# 3066H register map
File version: 1.0
Registers are 32-bit, access per field, reset 0x0 unless marked. A register's access mark holds for its fields unless they carry their own. Offsets are from the block's base; [hi:lo] are bit positions; {n}, {i} and the like mark numbered series.

## MCAN0 — MCAN0 peripheral interface
Base 0x14680000
Same registers: MCAN1 0x14684000, MCAN2 0x14688000
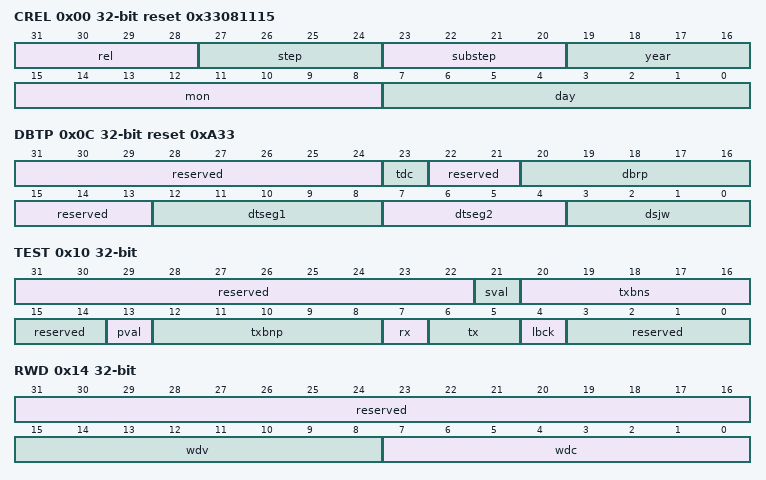
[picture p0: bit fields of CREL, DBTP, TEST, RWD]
0x00 CREL ro reset 0x33081115 — CREL为Core发布寄存器。
  [31:28] rel — 版本信息。
  [27:24] step — 版本信息。
  [23:20] substep — 版本信息。
  [19:16] year — 版本信息。
  [15:8] mon — 版本信息。
  [7:0] day — 版本信息。
0x04 ENDN ro reset 0x87654321 — ENDN为MCAN字节序寄存器。
  [31:0] etv — 字节序测试值。测试值为0x87654321。
0x0C DBTP reset 0xA33 — DBTP为MCAN数据位时间和预分频寄存器。 当MCAN通信时钟为8MHz时，复位值0x00000A33会将MCAN数据阶段（Data phase）的比特率配置为500kbit/s。通过DBTP配置的CAN FD数据阶段（Data phase）比特率不能小于通过NBTP配置的仲裁阶段（Arbitration phase）比特率。
  [31:24] reserved ro — 保留。
  [23] tdc rw — 发送延迟补偿。 0：禁止发送延迟补偿； 1：使能发送延迟补偿。
  [22:21] reserved ro — 保留。
  [20:16] dbrp rw — 数据比特率预分频。生成位时间片的MCAN通信时钟预分频值，位时间为该时间片的倍数。预分频有效值为0到31，当TDC=1时，范围被限制在0到1，硬件实际使用值为编程值加1。
  [15:13] reserved ro — 保留。
  [12:8] dtseg1 rw — 采样点之前的数据时间。有效值为0到31，硬件实际使用值为编程值加1。
  [7:4] dtseg2 rw — 采样点之后的数据时间。有效值为1到15，硬件实际使用值为编程值加1。
  [3:0] dsjw rw — 数据（重新）同步跳转宽度。有效值为0到15，硬件实际使用值为编程值加1。
0x10 TEST — TEST为MCAN测试寄存器。 bit[7]的复位值由CAN_RX引脚的实际电平决定。仅当CCCR[test]位被置1后，才能对该测试寄存器进行写访问。当CCCR[test]位被清零时，所有测试寄存器功能都会设为其复位值。回环模式和软件控制MCAN_TX引脚属于硬件测试模式。TX配置为非0b00时可能会干扰CAN总线上的消息传输。
  [31:22] reserved ro — 保留。
  [21] sval rw — TNBNS是否有效。 0：TXBNS的值无效； 1：TXBNS的值有效。
  [20:16] txbns rw — 已开始发送的缓冲区编号。 最后开始发送的发送缓冲区编号。 当SVAL位被置1时有效，有效范围为0~31。
  [15:14] reserved ro — 保留。
  [13] pval ro — TXNBP是否有效。 0：TXBNP的值无效； 1：TXBNP的值有效。
  [12:8] txbnp ro — 已准备好发送的缓冲区编号。 准备好发送的发送缓冲区编号。 当PVAL位被置1时有效，有效范围为0~31。
  [7] rx ro — 接收管脚。 监测到的CAN_RX管脚的实际值。 0：CAN总线为显性（CAN_RX=0）； 1：CAN总线为隐性（CAN_RX=1）。
  [6:5] tx rw — 发送引脚控制。 00：复位值，MCAN_TX引脚由CAN内核控制，在CAN位时间结束时更新； 01：可以在MCAN_TX引脚监测采样点； 10：MCAN_TX引脚输出显性电平（0）； 11：MCAN_TX引脚输出隐性电平（1）。
  [4] lbck rw — 环回模式。 0：复位值，禁止环回模式； 1：使能环回模式（详见26.3.2.10 外部环回模式和26.3.2.11 内部环回模式章节）。
  [3:0] reserved ro — 保留。
0x14 RWD — RWD为MCAN RAM看门狗寄存器。RAM看门狗会监视消息RAM的READY信号输出。对消息RAM进行访问时，会启动消息RAM看门狗计数器，该计数器的起始值由RWD[wdc]位进行配置。当消息RAM通过激活其READY信号输出，指示访问成功完成时，该计数器会重新载入RWD[wdc]的值。如果计数器递减为0之前消息RAM没有响应，计数器将停止计数，并将中断标志IR[wdi]位置1。RAM看门狗计数器由MCAN控制逻辑时钟计数。
  [31:16] reserved ro — 保留。
  [15:8] wdv ro — 看门狗计数值。 消息RAM看门狗计数器的实际值。
  [7:0] wdc rw — 看门狗配置。 消息RAM看门狗计数器的起始值。 如果使用初始值0x00，则计数器被禁止。
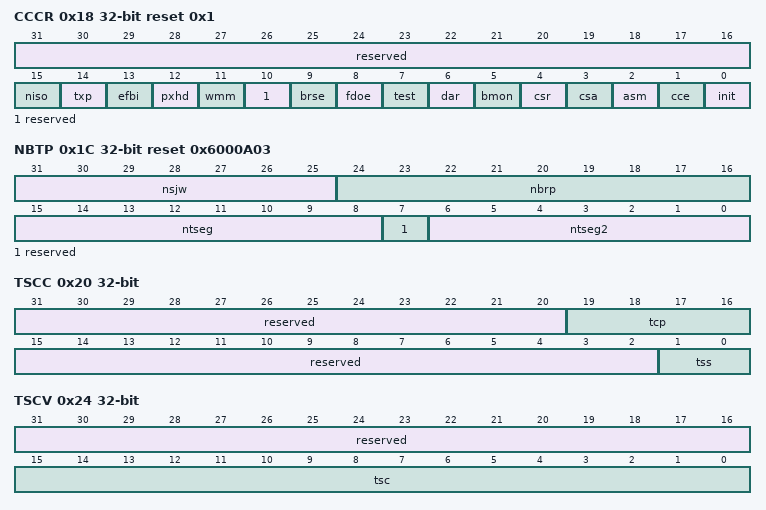
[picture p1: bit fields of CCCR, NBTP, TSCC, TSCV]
0x18 CCCR reset 0x1 — CCCR为MCAN CC控制寄存器。
  [31:16] reserved ro — 保留。
  [15] niso rw — 非ISO模式选择。 0：使用ISO 11898-1:2015规定的CAN FD帧格式； 1：使用Bosch CAN FD规范V1.0规定的CAN FD帧格式。
  [14] txp rw — 传输暂停。 若该位被置为1，则MCAN在成功传输完一帧数据后会暂停两个位时间，再进行下一帧数据的传输。 0：禁止传输暂停； 1：使能传输暂停。
  [13] efbi rw — 总线同步期间的边沿滤波。 0：禁止边沿滤波； 1：需要两个连续的显性tq才能检测硬同步边沿。
  [12] pxhd rw — 协议异常处理禁止。 0：使能协议异常处理； 1：禁止协议异常处理。 注意：当协议异常处理被禁止时，MCAN将在检测到协议异常条件时传输错误帧。
  [11] wmm rw — 宽消息标记。 当使用16位宽消息标记（WMM=1）时，发送事件FIFO中的16位内部时间戳是无效的。 0：使用8位消息标记； 1：使用16位消息标记，替换发送事件FIFO中的16位时间戳。
  [10] reserved ro — 保留。
  [9] brse rw — 比特率切换。 0：禁止发送时进行比特率切换； 1：使能发送时进行比特率切换。 注意：当CAN-FD模式无效（FDOE=0）时，BRSE的设置不起作用。
  [8] fdoe rw — FD模式使能。 0：禁止FD模式； 1：使能FD模式。
  [7] test rw — 测试模式使能。 0：正常模式，测试寄存器TEST保持复位值； 1：测试模式，使能写访问测试寄存器TEST。
  [6] dar rw — 禁止自动重发。 0：使能允许自动重发未成功发送的消息； 1：禁止自动重发。
  [5] bmon rw — 总线静默模式。 仅当CCE和INIT位均置1时，主机才能将MON位置1。此位可随时通过主机复位。 0：禁止总线静默模式； 1：使能总线静默模式。
  [4] csr rw — 时钟停止请求。 当已请求时钟停止时，在所有挂起的传输请求均已完成且CAN总线达到空闲状态之后，INIT位和CSA位将会依次被置1。 0：未请求时钟停止； 1：已请求时钟停止。
  [3] csa ro — 时钟停止确认。 0：未确认时钟停止请求； 1：已确认时钟停止请求，可以通过停止控制逻辑时钟和通信时钟将MCAN设为掉电状态。
  [2] asm rw — 受限操作模式。 仅当CCE和INIT均置1时，主机才能将ASM位置1。此位可随时通过主机复位。 有关受限工作模式的说明，请参阅受限工作模式章节。 0：正常模式； 1：受限工作模式。
  [1] cce rw — 配置更改使能。 0：CPU对受保护的配置寄存器无写访问权限； 1：CPU对受保护的配置寄存器有写访问权限（当INIT=1时）。
  [0] init rw — 初始化。 0：正常工作； 1：启动初始化； 注意：由于两个时钟域之间存在同步机制，INIT的值在写入后可能会有一定延迟才能被正确读取。因此，在重新设定INIT值之前，请确认之前的设定值确实已被写入。
0x1C NBTP reset 0x6000A03 — NBTP为MCAN标称位时间和预分频寄存器。仅当CCCR[cce]和CCCR[init]位均被置1时，才能对该寄存器进行写访问。CAN标称位时间的可编程范围为4到385个时间片（Time quanta，tq）。CAN时间片的可编程范围为1到512个MCAN通信时钟周期（Minimum time quantum， mtq）。 tq = (NBRP + 1)mtq。NTSEG1为Prop_Seg与Phase_Seg1之和。NTSEG2为Phase_Seg2。因此，位时间的长度为（编程值）[NTSEG1 + NTSEG2 + 3] tq 或（功能值）[Sync_Seg + Prop_Seg + Phase_Seg1 + Phase_Seg2] tq。信息处理时间（IPT）为零，这意味着下一位数据在采样点之后的第一个时钟边沿可用。 当MCAN时钟为8MHz时，复位值0x06000A03会将MCAN的比特率配置为500kbit/s。
  [31:25] nsjw rw — 标称（重）同步跳转宽度。 有效值为0到127，硬件实际使用值为编程值加1。
  [24:16] nbrp rw — 标称比特率预分频。 生成位时间片的MCAN通信时钟预分频值，位时间为该时间片的倍数。预分频有效值为0到511，硬件实际使用值为编程值加1。
  [15:8] ntseg rw — 采样点之前的标称时间段。 有效值为1到255，硬件实际使用值为编程值加1。
  [7] reserved ro — 保留。
  [6:0] ntseg2 rw — 采样点之后的标称时间段。 有效值为1到127，硬件实际使用值为编程值加1。
0x20 TSCC — TSCC为MCAN时间戳计数器配置寄存器。该寄存器用于配置内部16位时间戳计数器。内部时间戳处理的介绍请参见26.3.3 时间戳生成章节。
  [31:20] reserved ro — 保留。
  [19:16] tcp rw — 时间戳计数器预分频。 将时间戳和超时计数器时间单位配置为CAN位时间的1~16倍。 有效设定值为0~15，硬件实际使用值为编程值加1。
  [15:2] reserved ro — 保留。
  [1:0] tss rw — 时间戳选择。 00：时间戳计数器的值一直为0x0000； 01：时间戳计数器的值根据TCP递增； 10：禁止配置； 11：时间戳计数器的值一直为0x0000（等同于配置值“00”）。
0x24 TSCV access not given — TSCV为MCAN时间戳计数器值寄存器。
  [31:16] reserved ro — 保留。
  [15:0] tsc — 时间戳计数器。 在接收到或发送SOF（Start Of Frame）时捕获的内部时间戳计数器值。 当TSCC[tss]=0b01时，时间戳计数器以CAN位时间的1~16倍进行递增，具体倍数由TSCC[tcp]的设定值决定。计数回卷时，中断标志IR[tsw]会被置1。写操作会将计数器清零。 注意： “回卷”是指时间戳计数器的值从非零变为零，并不是由于TSCV的写操作引起的清零。字节访问时，对该寄存器的任何一个字节进行写操作都会导致时间戳寄存器被清零。
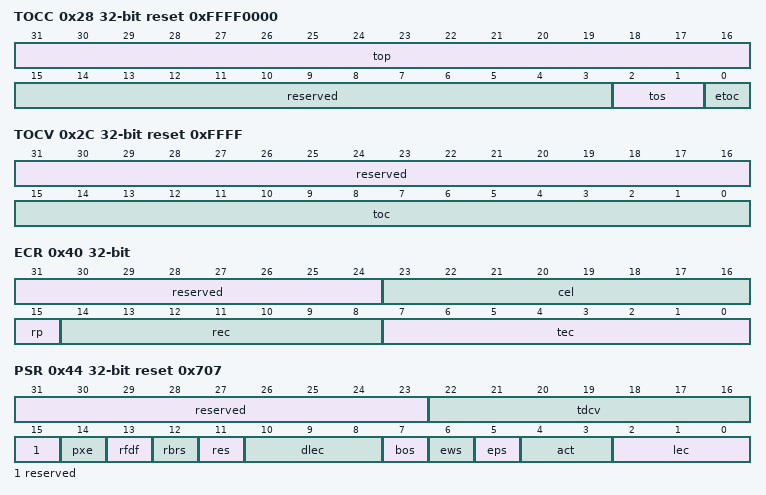
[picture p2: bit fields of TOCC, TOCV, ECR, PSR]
0x28 TOCC reset 0xFFFF0000 — TOCC为MCAN超时计数器配置寄存器。超时计数器的介绍请参见26.3.4 超时计数器章节。
  [31:16] top rw — 超时周期。 超时计数器（递减计数器）的起始值，配置超时周期。
  [15:3] reserved ro — 保留。
  [2:1] tos rw — 超时选择。 在连续模式下操作时，对TOCV进行写访问会将计数器预设为TOCC[top]配置的值，并继续向下递减。当超时计数器由其中一个FIFO控制时，空FIFO会将计数器预设为TOCC[top]配置的值。当第一个FIFO元素被存储后，计数器开始递减计数。 00：连续模式； 01：由发送事件FIFO控制超时； 10：由接收FIFO0控制超时； 11：由接收FIFO1控制超时。
  [0] etoc rw — 超时计数器使能。 0：禁止超时计数器； 1：使能超时计数器。
0x2C TOCV access not given reset 0xFFFF — TOCV为MCAN超时计数器值寄存器。
  [31:16] reserved ro — 保留。
  [15:0] toc — 超时计数器。 超时计数器以CAN位时间的1~16倍进行递减，具体倍数由TSCC[tcp]的设定值决定。 当计数器递减到零时，中断标志位IR[too]会被置1，计数器停止计数。可以通过TOCC[tos]来设置启动和复位（或重启）条件。 注意：字节访问时，当TOCC[tos]=0b00时，对该寄存器的任何一个字节进行写操作都会将超时计数器预设为TOCC[top]配置的值。
0x40 ECR ro — ECR为MCAN错误计数器寄存器。
  [31:24] reserved — 保留。
  [23:16] cel — CAN错误记录。 当CAN协议错误导致发送错误计数器TEC或接收错误计数器REC递增时，该错误记录计数器CEL都会递增。计数器值达到0xFF时，会停止计数。只有RP位置位但REC没有变化时，CEL不会递增。CEL在REC和TEC增加后递增。 对CEL进行读访问会复位计数器。计数器值达到0xFF时，停止计数，TEC或REC下一次增加时中断标志IR[elo]置位。 注意：字节访问时，读取寄存器的字节2会将CEL清零，读取字节3、1或0没有影响。如果CCCR[asm]被置为1，则检测到CAN协议错误时，CAN协议控制器不会使TEC和REC递增，但CEL仍会递增。
  [15] rp — 接收错误被动。 0：接收错误计数器低于错误被动级别128； 1：接收错误计数器已达到错误被动级别128。
  [14:8] rec — 接收错误计数器。 接收错误计数器的实际状态，计数值范围为0x00~0x7F。
  [7:0] tec — 发送错误计数器。 发送错误计数器的实际状态，计数值范围为0x00~0xFF。
0x44 PSR ro reset 0x707 — PSR为MCAN协议状态寄存器。
  [31:23] reserved — 保留。
  [22:16] tdcv — 发送延迟补偿值。 实际的发送延迟补偿值，有效值为0~127个mtq。 第二采样点（Secondary Sample Point， SSP）的位置，由CAN_TX引脚到CAN_RX引脚之间测得的迟延值与TDCR[tdco]之和决定。在数据阶段（Data phase），SSP位置是发送位的起始点与第二采样点间的mtq数。
  [15] reserved — 保留。
  [14] pxe — 协议异常事件。 0：自上次读访问后未发生协议异常事件； 1：已发生协议异常事件； 访问类型为RX：进行读访问时复位。 注意：字节访问时，读取寄存器的字节0会将PXE清零，读取字节3/2/1没有影响。
  [13] rfdf — 收到CAN-FD消息。 此位的置位与接收过滤无关。 0：自从上次被CPU清零后未收到CAN FD格式的消息； 1：收到FDF标志为1的CAN FD格式的消息。 注意：字节访问时，读取寄存器的字节0会将RFDF清零，读取字节3/2/1没有影响。
  [12] rbrs — 上次收到的CAN-FD消息的BRS标志。 该位与RFDF一起置位，与接收过滤无关。 0：上次收到的CAN FD消息的BRS标志未置位； 1：上次收到的CAN FD消息的BRS标志已置位。 注意：字节访问时，读取寄存器的字节0会将RBRS清零，读取字节3/2/1没有影响。
  [11] res — 上次收到的CAN-FD消息的ESI标志。 该位与RFDF一起被设置，与验收过滤器无关。 0：上次收到的CAN FD消息的ESI标志未置位； 1：上次收到的CAN FD消息的ESI标志已置位。 注意：字节访问时，读取寄存器的字节0会将RESI清零，读取字节3/2/1没有影响。
  [10:8] dlec — 数据阶段最后一次错误码。 在设置了BRS标志的CAN FD帧的数据阶段（Data phase）中发生的最后一个错误的类型。错误码与LEC相同。当设置了BRS标志的CAN FD帧传输（接收或发送）没有错误时，DLEC将被清零。 注意：字节访问时，读取寄存器的字节0会将DLEC设置为0b111，读取字节3/2/1没有影响。
  [7] bos — Buss_Off状态。 0：MCAN未处于Bus_Off状态； 1：MCAN处于Bus_Off状态。
  [6] ews — 警告状态（Error_Warning）。 0：两个错误计数器均小于错误警告（Error_Warning）上限96； 1：至少有一个错误计数器已达到错误警告（Error_Warning）上限96。
  [5] eps — 错误被动（Error_Active）。 0：MCAN处于错误主动（Error_Active）状态。MCAN正常参与总线通信，并在检测到错误时发送主动错误标志。 1：MCAN处于错误被动（Error_Passive）状态。
  [4:3] act — 通信状态。 监测MCAN的通信状态。 00：同步中，节点正在进行CAN通信同步； 01：空闲，节点既不是接收节点也不是发送节点； 10：接收，节点作为接收节点工作； 11：发送，节点作为发送节点工作。 注意：协议异常事件会将ACT设为00。
  [2:0] lec — 最后一次错误码。 000：没有错误（NoError）。自成功接收或发送使LEC复位之后，没有错误发生； 001：填充错误（StuffError）。在已接收到的消息中，某一部分出现了5个以上的相同位，这种情况是不允许的； 010：格式错误（FormError）。已接收帧的固定格式部分有格式错误； 011：ACK错误（ACKError）。MCAN发送的消息没有被其他节点确认； 100：Bit1错误（Bit1Error）。在消息的发送过程中（仲裁场Arbitrationfield除外），设备发送了一个隐性电平（逻辑值1），但是监测到的总线电平为显性（逻辑值0）； 101：bit0错误（bit0Error）。在消息的发送过程中（包括ACK位、主动错误标志、过载标志），设备发送了一个显性电平（数据或ID的逻辑值0），但是监测到的总线电平为隐性（逻辑值1）。在总线Bus_Off恢复期间，每次监测到11位隐性位序列时，都会设置为该状态。这样，CPU就能够监测总线恢复序列的进程（表明总线未卡在显性状态或持续受到干扰）； 110：CRC错误（CRCError）。已接收消息的CRC有错误。收到的CRC和用接收到的数据计算出的CRC不匹配； 111：无变化（NoChange）。对协议状态寄存器的任何读访问会将LEC重新初始化为7。当LEC显示值为7时，表示自上次CPU对协议状态寄存器进行读访问之后，没有检测到CAN总线事件。 注意： 当设置了BRS标志的CANFD帧已经到达数据阶段（Dataphase）时，下一个CAN事件（错误或有效帧）将显示在DLEC中而不是LEC中。CANFDCRC序列中的固定填充位的错误将显示为格式错误（FormError）而不是填充错误（StuffError）。Bus_Off恢复序列（请参见ISO11898-1:2015）不能通过置位或清零CCCR[init]来缩短。如果设备进入Bus_Off状态，它将自动置位CCCR[init]，停止所有总线活动。一旦CCCR[init]被CPU清零，设备在恢复正常操作之前，将等待129个总线空闲（129*11个连续的隐性位）。在Bus_Off恢复序列结束时，错误管理计数器将被复位。在清零CCCR[init]后的等待期间，每次监测到一个11位隐性序列时，就向PSR[lec]写入一个Bit0错误码，使CPU能够随时检查CAN总线是否处于显性状态或持续被干扰，并监测Bus_Off恢复序列。ECR[rec]用于对这些序列进行计数。字节操作时，读取寄存器的字节0会将LEC设置为111，读取字节3/2/1没有影响。
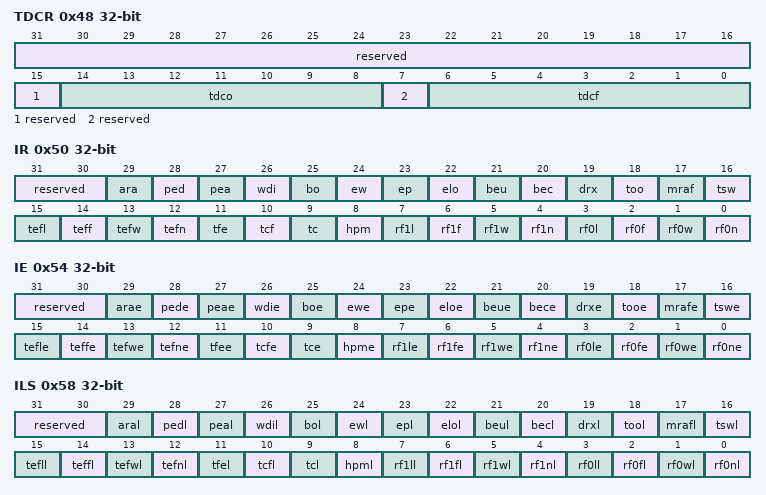
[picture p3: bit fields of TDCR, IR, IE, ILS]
0x48 TDCR — TDCR为MCAN发送延迟补偿寄存器。
  [31:15] reserved ro — 保留。
  [14:8] tdco rw — 发送延迟补偿SSP偏移。 该偏移值是指，从MCAN_TX引脚到MCAN_RX引脚测得的延迟与第二采样点（SSP）之间的距离。有效设定值为0~127mtq。
  [7] reserved ro — 保留。
  [6:0] tdcf rw — 发送延迟补偿滤波窗口宽度。 定义SSP位置的最小值，对于发送延迟的测量，将忽略MCAN_RX引脚上会导致SSP位置提前的显性边沿。当TDCF设定值大于TDCO时，该功能被启用。有效设定值为0~127mtq。
0x50 IR — IR为MCAN中断寄存器。当如下列表中的一个条件被检测到时，对应标志位会置位。在主机将标志位清零之前，保持置位状态。所有标志位写1清零，写0无影响。硬复位会将寄存器清零。是否产生中断，由寄存器IE控制；哪条中断线产生中断，由寄存器ILS控制。
  [31:30] reserved ro — 保留。
  [29] ara rw — 访问保留地址（Access to Reserved Address）。 0：未对保留地址进行访问； 1：已对保留地址进行访问。
  [28] ped rw — 数据阶段协议错误（使用数据位时间）（Protocol Error in Data Phase （Data Bit Timeis used））。 0：未检测到数据阶段协议错误； 1：检测到数据阶段协议错误（PSR[dlec]≠0/7）。
  [27] pea rw — 仲裁阶段协议错误（使用标称位时间）（Protocol Error in Arbitration Phase （Nominal Bit Time is used））。 0：未检测到仲裁阶段协议错误； 1：检测到仲裁阶段协议错误（PSR[lec]≠0/7）。
  [26] wdi rw — 看门狗中断（Watchdog Interrupt）。 0：未发生消息RAM看门狗事件； 1：因READY信号缺失而发生消息RAM看门狗事件。
  [25] bo rw — Bus_Off状态（Bus_Off Status）。 0：Bus_Off状态未改变； 1：Bus_Off状态已改变。
  [24] ew rw — 警告状态（Warning Status）。 0：错误警告（Error_Warning）状态未改变； 1：错误警告（Error_Warning）状态已改变。
  [23] ep rw — 错误被动（Error Passive）。 0：错误被动（Error_Passive）状态未改变； 1：错误被动（Error_Passive）状态已改变。
  [22] elo rw — 错误记录溢出（Error Logging Overflow）。 0：CAN错误记录计数器未溢出； 1：CAN错误记录计数器已溢出。
  [21] beu rw — 位错误未纠正（Bit Error Uncorrected）。 0：从消息RAM读取时未检测到错误； 1：当MCANRAM_CKCR[ECCMOD]不为0时，从消息RAM读取时检测到位错误且未纠正。 注意：BEU置位的同时CCCR[init]置位。
  [20] bec rw — 位错误已纠正（Bit Error Corrected）。 0：从消息RAM读取时未检测到错误位； 1：当MCANRAM_CKCR[ECCMOD]不为0时，从消息RAM读取时检测到位错误且已纠正。
  [19] drx rw — 消息存储到专用接收缓冲区（Message stored to Dedicated Rx Buffer）。 每当收到的消息已存储到专用接收缓冲区时，都会置位该标志。 0：接收缓存区未更新； 1：至少有一条消息已存储到接收缓冲区。
  [18] too rw — 发生超时（Timeout Occurred）。 0：未发生超时； 1：已发生超时。
  [17] mraf rw — 消息RAM访问失败（Message RAM Access Failure）。 0：未发生消息RAM访问失败； 1：发生了消息RAM访问失败。 接收处理中置位条件： 在接收到后续消息的仲裁场（Arbitration field）之前，尚未完成对已接收消息的接收过滤或存储。在这种情况下，接收过滤或消息存储被终止，接收处理单元将开始处理后续消息。 无法向消息RAM写入消息，消息存储将终止。 在这两种情况下，FIFO放入索引都不会更新，专用接收缓冲区的新数据标志不会置位，当下一条消息存储到该位置时，已部分存储的消息会被覆盖。 发送处理中置位条件： 发送处理单元无法及时从消息RAM读取消息。在这种情况下，消息发送将终止。 在发送处理单元访问失败的情况下，MCAN被切换到受限工作模式（详见26.3.2.5 受限工作模式章节）。要退出受限工作模式，主机CPU必须复位CCCR[asm]。
  [16] tsw rw — 时间戳回卷（Timestamp Wraparound）。 0：时间戳计数器未回卷； 1：时间戳计数器已回卷。
  [15] tefl rw — 发送事件FIFO元素丢失（Tx Event FIFO Element Lost）。 0：发送事件FIFO元素未丢失； 1：发送事件FIFO元素有丢失；对空间大小为0的发送事件FIFO进行写操作时，该位也会置位。
  [14] teff rw — 发送事件FIFO已满（Tx Event FIFO Full）。 0：发送事件FIFO未满； 1：发送事件FIFO已满。
  [13] tefw rw — 发送事件FIFO到达水位线（Tx Event FIFO Watermark Reached）。 0：发送事件FIFO的填充级别低于水位线； 1：发送事件FIFO的填充级别达到水位线。
  [12] tefn rw — 发送事件FIFO新条目（Tx Event FIFO New Entry）。 0：发送事件FIFO无变化； 1：发送处理单元写入了发送事件FIFO元素。
  [11] tfe rw — 发送FIFO为空（Tx FIFO Empty）。 0：发送FIFO非空； 1：发送FIFO为空。
  [10] tcf rw — 发送取消已完成（Transmission Cancellation Finished）。 0：发送取消未完成； 1：发送取消已完成。
  [9] tc rw — 发送完成（Transmission Completed）。 0：发送未完成； 1：发送已完成。
  [8] hpm rw — 高优先级消息（High Priority Message）。 0：未收到高优先级消息； 1：已收到高优先级消息。
  [7] rf1l rw — 接收FIFO1消息丢失（Rx FIFO 1 Message Lost）。 0：接收FIFO1消息未丢失； 1：接收FIFO1消息有丢失；对空间大小为0的接收FIFO1进行写操作时，该位也会置位。
  [6] rf1f rw — 接收FIFO1已满（Rx FIFO 1 Full）。 0：接收FIFO1未满； 1：接收FIFO1已满。
  [5] rf1w rw — 接收FIFO1到达水位线（Rx FIFO 1 Watermark Reached）。 0：接收FIFO1的填充级别低于水位线； 1：接收FIFO1的填充级别达到水位线。
  [4] rf1n rw — 接收FIFO1新消息（Rx FIFO 1 New Message）。 0：没有新消息写入接收FIFO1； 1：有新消息写入接收FIFO1。
  [3] rf0l rw — 接收FIFO0消息丢失（Rx FIFO 0 Message Lost）。 0：接收FIFO0消息未丢失； 1：接收FIFO0消息有丢失；对空间大小为0的接收FIFO0进行写操作时，该位也会置位。
  [2] rf0f rw — 接收FIFO0已满（Rx FIFO 0 Full）。 0：接收FIFO0未满； 1：接收FIFO0已满。
  [1] rf0w rw — 接收FIFO0到达水位线（Rx FIFO 0 Watermark Reached）。 0：接收FIFO0的填充级别低于水位线； 1：接收FIFO0的填充级别达到水位线。
  [0] rf0n rw — 接收FIFO0新消息（Rx FIFO 0 New Message）。 0：没有新消息写入接收FIFO0； 1：有新消息写入接收FIFO0。
0x54 IE — IE为MCAN中断使能寄存器。中断使能寄存器中的设置，决定中断寄存器IR中的哪些状态变化会指示在中断线上。
  [31:30] reserved ro — 保留。
  [29] arae rw — 访问保留地址使能（Access to Reserved Address Enable）。 0：禁止中断； 1：使能中断。
  [28] pede rw — 数据阶段的协议错误使能（Protocol Error in Data Phase Enable）。 0：禁止中断； 1：使能中断。
  [27] peae rw — 仲裁阶段中的协议错误使能（Protocol Error in Arbitration Phase Enable）。 0：禁止中断； 1：使能中断。
  [26] wdie rw — 看门狗中断使能（Watchdog Interrupt Enable）。 0：禁止中断； 1：使能中断。
  [25] boe rw — Bus_Off状态中断（Bus_Off Status Interrupt Enable）。 0：禁止中断； 1：使能中断。
  [24] ewe rw — 警告状态中断使能（Warning Status Interrupt Enable）。 0：禁止中断； 1：使能中断。
  [23] epe rw — 错误被动中断使能（Error Passive Interrupt Enable）。 0：禁止中断； 1：使能中断。
  [22] eloe rw — 错误记录溢出中断使能（Error Logging Overflow Interrupt Enable）。 0：禁止中断； 1：使能中断。
  [21] beue rw — 位错误未纠正中断使能（Bit Error Uncorrected Interrupt Enable）。 0：禁止中断； 1：使能中断。
  [20] bece rw — 位错误已纠正中断使能（Bit Error Corrected Interrupt Enable）。 0：禁止中断； 1：使能中断。
  [19] drxe rw — 消息存储到专用接收缓冲区中断使能（Message stored to Dedicated Rx Buffer Interrupt Enable）。 0：禁止中断； 1：使能中断。
  [18] tooe rw — 发生超时中断使能（Timeout Occurred Interrupt Enable）。 0：禁止中断； 1：使能中断。
  [17] mrafe rw — 消息 RAM 访问失败中断使能（Message RAM Access Failure Interrupt Enable）。 0：禁止中断； 1：使能中断。
  [16] tswe rw — 时间戳回卷中断使能（Timestamp Wraparound Interrupt Enable）。 0：禁止中断； 1：使能中断。
  [15] tefle rw — 发送事件FIFO元素丢失中断使能（Tx Event FIFO Element Lost Interrupt Enable）。 0：禁止中断； 1：使能中断。
  [14] teffe rw — 发送事件FIFO满中断使能（Tx Event FIFO Full Interrupt Enable）。 0：禁止中断； 1：使能中断。
  [13] tefwe rw — 发送事件FIFO到达水位线中断使能（Tx Event FIFO Watermark Reached Interrupt Enable）。 0：禁止中断； 1：使能中断。
  [12] tefne rw — 发送事件FIFO新条目中断使能（Tx Event FIFO New Entry Interrupt Enable）。 0：禁止中断； 1：使能中断。
  [11] tfee rw — 发送FIFO空中断使能（Tx FIFO Empty Interrupt Enable）。 0：禁止中断； 1：使能中断。
  [10] tcfe rw — 发送取消已完成中断使能（Transmission Cancellation Finished Interrupt Enable）。 0：禁止中断； 1：使能中断。
  [9] tce rw — 发送完成中断使能（Transmission Completed Interrupt Enable）。 0：禁止中断； 1：使能中断。
  [8] hpme rw — 高优先级消息中断使能（High Priority Message Interrupt Enable）。 0：禁止中断； 1：使能中断。
  [7] rf1le rw — 接收FIFO1消息丢失中断使能（Rx FIFO 1 Message Lost Interrupt Enable）。 0：禁止中断； 1：使能中断。
  [6] rf1fe rw — 接收FIFO1满中断使能（Rx FIFO 1 Full Interrupt Enable）。 0：禁止中断； 1：使能中断。
  [5] rf1we rw — 接收FIFO1到达水位线中断使能（Rx FIFO 1 Watermark Reached Interrupt Enable）。 0：禁止中断； 1：使能中断。
  [4] rf1ne rw — 接收FIFO1新消息中断使能（Rx FIFO 1 New Message Interrupt Enable）。 0：禁止中断； 1：使能中断。
  [3] rf0le rw — 接收FIFO0消息丢失中断使能（Rx FIFO 0 Message Lost Interrupt Enable）。 0：禁止中断； 1：使能中断。
  [2] rf0fe rw — 接收FIFO0满中断使能（Rx FIFO 0 Full Interrupt Enable）。 0：禁止中断； 1：使能中断。
  [1] rf0we rw — 接收FIFO 0到达水位线中断使能（Rx FIFO 0 Watermark Reached Interrupt Enable）。 0：禁止中断； 1：使能中断。
  [0] rf0ne rw — 接收FIFO0新消息中断使能（Rx FIFO 0 New Message Interrupt Enable）。 0：禁止中断； 1：使能中断。
0x58 ILS — ILS为MCAN中断线选择寄存器。中断线选择寄存器，将中断寄存器（MCAN_IR）中特定中断标志生成的中断分配到两条中断线之一。要产生中断，必须通过ILE[eint0]和ILE[eint1]使能相应的中断线。
  [31:30] reserved ro — 保留。
  [29] aral rw — 访问保留地址中断线（Access to Reserved Address Line）。 0：选择中断线0； 1：选择中断线1。
  [28] pedl rw — 数据阶段协议错误中断线（Protocol Error in Data Phase Line）。 0：选择中断线0； 1：选择中断线1。
  [27] peal rw — 仲裁阶段协议错误中断线（Protocol Error in Arbitration Phase Line）。 0：选择中断线0； 1：选择中断线1。
  [26] wdil rw — 看门狗中断线（Watchdog Interrupt Line）。 0：选择中断线0； 1：选择中断线1。
  [25] bol rw — Bus_Off状态中断线（Bus_Off Status Interrupt Line）。 0：选择中断线0； 1：选择中断线1。
  [24] ewl rw — 警告状态中断线（Warning Status Interrupt Line）。 0：选择中断线0； 1：选择中断线1。
  [23] epl rw — 错误被动中断线（Error Passive Interrupt Line）。 0：选择中断线0； 1：选择中断线1。
  [22] elol rw — 错误记录溢出中断线（Error Logging Overflow Interrupt Line）。 0：选择中断线0； 1：选择中断线1。
  [21] beul rw — 位错误未纠正中断线（Bit Error Uncorrected Interrupt Line）。 0：选择中断线0； 1：选择中断线1。
  [20] becl rw — 位错误已纠正中断线（Bit Error Corrected Interrupt Line）。 0：选择中断线0； 1：选择中断线1。
  [19] drxl rw — 消息存储到专用接收缓冲区中断线（Message stored to Dedicated Rx Buffer Interrupt Line）。 0：选择中断线0； 1：选择中断线1。
  [18] tool rw — 发生超时中断线（Timeout Occurred Interrupt Line）。 0：选择中断线0； 1：选择中断线1。
  [17] mrafl rw — 消息RAM访问失败中断线（Message RAM Access Failure Interrupt Line）。 0：选择中断线0； 1：选择中断线1。
  [16] tswl rw — 时间戳回卷中断线（Timestamp Wraparound Interrupt Line）。 0：选择中断线0； 1：选择中断线1。
  [15] tefll rw — 发送事件FIFO元素丢失中断线（Tx Event FIFO Element Lost Interrupt Line）。 0：选择中断线0； 1：选择中断线1。
  [14] teffl rw — 发送事件FIFO已满中断线（Tx Event FIFO Full Interrupt Line）。 0：选择中断线0； 1：选择中断线1。
  [13] tefwl rw — 发送事件FIFO到达水位线中断线（Tx Event FIFO Watermark Reached Interrupt Line）。 0：选择中断线0； 1：选择中断线1。
  [12] tefnl rw — 发送事件FIFO新条目中断线（Tx Event FIFO New Entry Interrupt Line）。 0：选择中断线0； 1：选择中断线1。
  [11] tfel rw — 发送FIFO为空中断线（Tx FIFO Empty Interrupt Line）。 0：选择中断线0； 1：选择中断线1。
  [10] tcfl rw — 发送取消已完成中断线（Transmission Cancellation Finished Interrupt Line）。 0：选择中断线0； 1：选择中断线1。
  [9] tcl rw — 发送完成中断线（Transmission Completed Interrupt Line）。 0：选择中断线0； 1：选择中断线1。
  [8] hpml rw — 高优先级消息中断线（High Priority Message Interrupt Line）。 0：选择中断线0； 1：选择中断线1。
  [7] rf1ll rw — 接收FIFO1消息丢失中断线（Rx FIFO 1 Message Lost Interrupt Line）。 0：选择中断线0； 1：选择中断线1。
  [6] rf1fl rw — 接收FIFO1已满中断线（Rx FIFO 1 Full Interrupt Line）。 0：选择中断线0； 1：选择中断线1。
  [5] rf1wl rw — 接收FIFO1到达水位线中断线（Rx FIFO 1 Watermark Reached Interrupt Line）。 0：选择中断线0； 1：选择中断线1。
  [4] rf1nl rw — 接收FIFO1新消息中断线（Rx FIFO 1 New Message Interrupt Line）。 0：选择中断线0； 1：选择中断线1。
  [3] rf0ll rw — 接收FIFO0消息丢失中断线（Rx FIFO 0 Message Lost Interrupt Line）。 0：选择中断线0； 1：选择中断线1。
  [2] rf0fl rw — 接收FIFO0已已满中断线（Rx FIFO 0 Full Interrupt Line）。 0：选择中断线0； 1：选择中断线1。
  [1] rf0wl rw — 接收FIFO0到达水位线中断线（Rx FIFO 0 Watermark Reached Interrupt Line）。 0：选择中断线0； 1：选择中断线1。
  [0] rf0nl rw — 接收FIFO0新消息中断线（Rx FIFO 0 New Message Interrupt Line）。 0：选择中断线0； 1：选择中断线1。
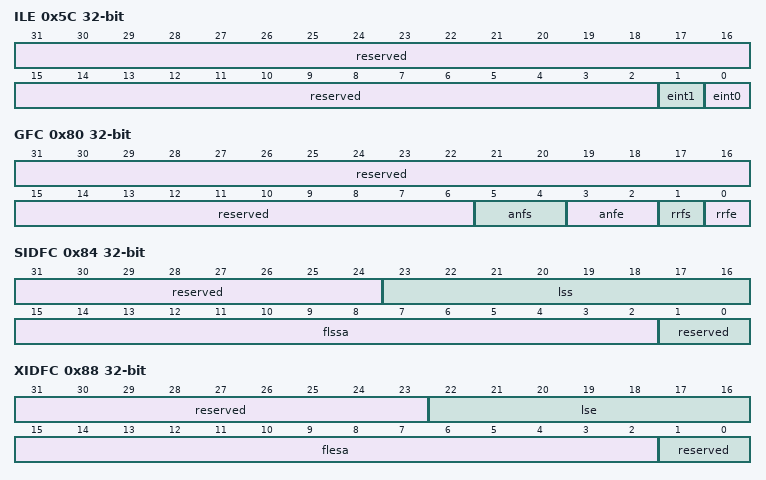
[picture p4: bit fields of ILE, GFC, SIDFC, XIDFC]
0x5C ILE — ILE为MCAN中断线使能寄存器。连接到CPU的两条中断线中的每一条，都可以通过设置eint0和eint1分别使能或禁用。
  [31:2] reserved ro — 保留。
  [1] eint1 rw — 中断线1使能。 0：中断线1禁止； 1：中断线1使能。
  [0] eint0 rw — 中断线0使能。 0：中断线0禁止； 1：中断线0使能。
0x80 GFC — GFC为MCAN全局过滤器配置寄存器。用于消息ID过滤的全局设置。全局过滤器配置，控制标准消息和扩展消息的过滤路径。
  [31:6] reserved ro — 保留。
  [5:4] anfs rw — 接受不匹配的标准帧。 定义如何处理，已接收的与过滤器列表任何元素都不匹配的11位标准ID消息。 00：在接收FIFO0中接受不匹配的标准帧； 01：在接收FIFO1中接受不匹配的标准帧； 10：拒绝不匹配的标准帧； 11：拒绝不匹配的标准帧。
  [3:2] anfe rw — 接受不匹配的扩展帧。 定义如何处理，已接收的与过滤器列表任何元素都不匹配的29位扩展ID消息。 00：在接收FIFO0中接受不匹配的扩展帧； 01：在接收FIFO1中接受不匹配的扩展帧； 10：拒绝不匹配的扩展帧； 11：拒绝不匹配的扩展帧。
  [1] rrfs rw — 拒绝远程标准帧。 0：过滤11位标准ID的远程帧； 1：拒绝所有11位标准ID的远程帧。
  [0] rrfe rw — 拒绝远程扩展帧。 0：过滤29位扩展ID的远程帧； 1：拒绝所有29位扩展ID的远程帧。
0x84 SIDFC — SIDFC为MCAN标准ID过滤器配置寄存器。用于11位标准ID过滤器的设置。标准ID过滤器配置，控制标准消息的过滤路径。
  [31:24] reserved ro — 保留。
  [23:16] lss rw — 标准ID过滤器列表大小。 0x00：无标准ID过滤器； 0x01~0x80：标准ID过滤器元素数量； ＞0x80：大于128的设定值被解析为128。
  [15:2] flssa rw — 标准ID过滤器列表起始地址。 设置标准ID过滤器列表的起始地址（32位字地址）。
  [1:0] reserved ro — 保留。
0x88 XIDFC — XIDFC为MCAN扩展ID过滤器配置寄存器。用于29位扩展ID过滤器的设置。扩展ID过滤器配置，控制扩展消息的过滤路径。
  [31:23] reserved ro — 保留。
  [22:16] lse rw — 扩展ID过滤器列表大小。 0x00：无扩展ID过滤器； 0x01~0x40：扩展ID过滤器元素数量； ＞0x40：大于64的设定值被解析为64。
  [15:2] flesa rw — 扩展ID过滤器列表起始地址。 扩展ID过滤器列表的起始地址（32位字地址）。
  [1:0] reserved ro — 保留。
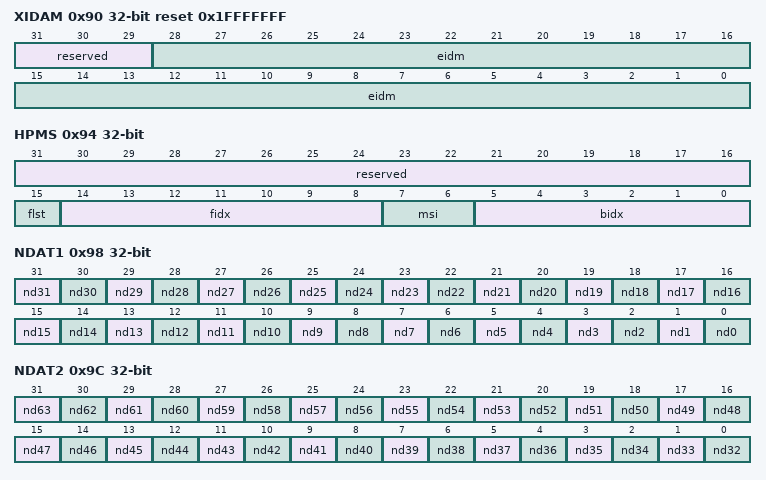
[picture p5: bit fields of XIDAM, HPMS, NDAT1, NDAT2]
0x90 XIDAM reset 0x1FFFFFFF — XIDAM为MCAN扩展ID与掩码寄存器。
  [31:29] reserved ro — 保留。
  [28:0] eidm rw — 扩展ID掩码。 对于扩展帧的接收过滤，会将此位域与已接收帧的ID进行与运算。用于屏蔽SAE J1939中的29位ID。所有位的复位值都被设置为1，掩码无效。
0x94 HPMS ro — HPMS为MCAN高优先级消息状态寄存器。配置为生成优先级事件的消息ID过滤器元素，每次匹配时都会更新此寄存器。这可用于监测收到的高优先级消息的状态，并可对这些消息进行快速访问。
  [31:16] reserved — 保留。
  [15] flst — 过滤器列表。 指示匹配的过滤器列表。 0：标准过滤器列表； 1：扩展过滤器列表。
  [14:8] fidx — 过滤器索引。 匹配的过滤器元素的索引。范围为0到SIDFC[lss]减1或XIDFC[lse]减1。
  [7:6] msi — 消息存储器指示符。 00：未选择FIFO； 01：FIFO消息丢失； 10：消息存储在FIFO0中； 11：消息存储在FIFO1中。
  [5:0] bidx — 缓存区索引。 存储消息的接收FIFO元素的索引。仅当msi=1X时有效。
0x98 NDAT1 rw — NDAT1为MCAN新数据1寄存器。
  [31] nd31 — 该寄存器保存接收缓冲区31的新数据标志。当接收帧更新接收缓冲区时，对应的标志位会置1。在主机将标志位清零之前，标志位保持置1状态。通过向对应位写1将标志位清零，写入0不起任何作用。硬复位会将寄存器清零。 0：接收缓冲区未更新； 1：接收缓冲区通过新消息更新。
  [n] nd{n} (n=0..30) — 该寄存器保存接收缓冲区{n}的新数据标志。
0x9C NDAT2 rw — NDAT2为MCAN新数据2寄存器。
  [31] nd63 — 该寄存器保存接收缓冲区63的新数据标志。当接收帧更新接收缓冲区时，对应的标志位会置1。在主机将标志位清零之前，标志位保持置1状态。通过向对应位写1将标志位清零，写入0不起任何作用。硬复位会将寄存器清零。 0：接收缓冲区未更新； 1：接收缓冲区通过新消息更新。
  [n-32] nd{n} (n=32..62) — 该寄存器保存接收缓冲区{n}的新数据标志。
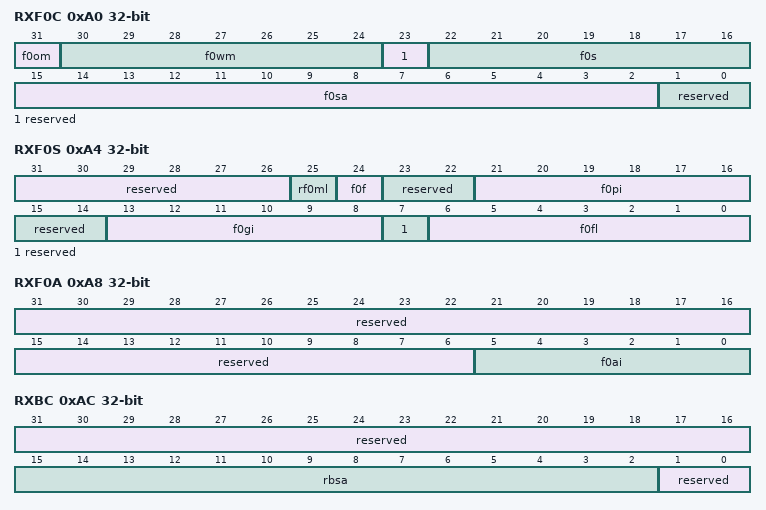
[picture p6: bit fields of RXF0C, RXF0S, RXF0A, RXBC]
0xA0 RXF0C — RXF0C为MCAN接收FIFO0配置寄存器。
  [31] f0om rw — 接收FIFO0工作模式。 FIFO0可工作在阻塞模式（Blocking mode）或覆盖模式（Overwrite mode）。 0：接收FIFO0为阻塞模式； 1：接收FIFO0为覆盖模式。
  [30:24] f0wm rw — 接收FIFO0水位线。 0x00：禁止接收FIFO0水位线中断； 0x01~0x40：接收FIFO0水位线中断（IR[rf0w]）的级别； ＞0x40：禁止接收FIFO0水位线中断。
  [23] reserved ro — 保留。
  [22:16] f0s rw — 接收FIFO0大小。 0x00：无接收FIFO0； 0x01~0x40：接收FIFO0元素数量； ＞0x40：大于64的设定值被解析为64。 接收FIFO0元素的索引为0到F0S减1。
  [15:2] f0sa rw — 接收FIFO0起始地址。 消息RAM中接收FIFO0的起始地址（32位字地址）。
  [1:0] reserved ro — 保留。
0xA4 RXF0S ro — RXF0S为MCAN接收FIFO0状态寄存器。
  [31:26] reserved — 保留。
  [25] rf0ml — 接收FIFO0消息丢失。 该位是中断标志IR[rf0l]的副本。当IR[rf0l]被复位时，该位也被复位。 0：接收FIFO0无消息丢失； 1：接收FIFO0有消息丢失；对空间大小为0的接收FIFO0进行写操作时，该位也会置位。 注意：当RXF0C[f0om]=1时，覆盖最早的消息，不会置位该标志位。
  [24] f0f — 接收FIFO0满。 0：接收FIFO0未满； 1：接收FIFO0已满。
  [23:22] reserved — 保留。
  [21:16] f0pi — 接收FIFO0放入索引。 接收FIFO0写入索引指针，范围0~63。
  [15:14] reserved — 保留。
  [13:8] f0gi — 接收FIFO0获取索引。 接收FIFO0读取索引指针，范围0~63。
  [7] reserved — 保留。
  [6:0] f0fl — 接收FIFO0填充级别。 接收FIFO0中存储的元素数量，范围0~64。
0xA8 RXF0A — RXF0A为MCAN接收FIFO0确认寄存器。
  [31:6] reserved ro — 保留。
  [5:0] f0ai rw — 接收FIFO0确认索引。 主机从接收FIFO0读取消息或消息序列后，必须将从接收FIFO0中读取的最后一个元素的缓冲区索引写入F0AI。此操作会将接收FIFO0获取索引RXF0S[f0gi]设为F0AI加1，并会更新FIFO0填充级别RXF0S[f0fl]。
0xAC RXBC — RXBC为MCAN接收缓冲区配置寄存器。
  [31:16] reserved ro — 保留。
  [15:2] rbsa rw — 接收缓冲区的起始地址。 配置消息RAM中接收缓冲区的起始地址（32位地址），也用于引用调试消息A、B、C。
  [1:0] reserved ro — 保留。
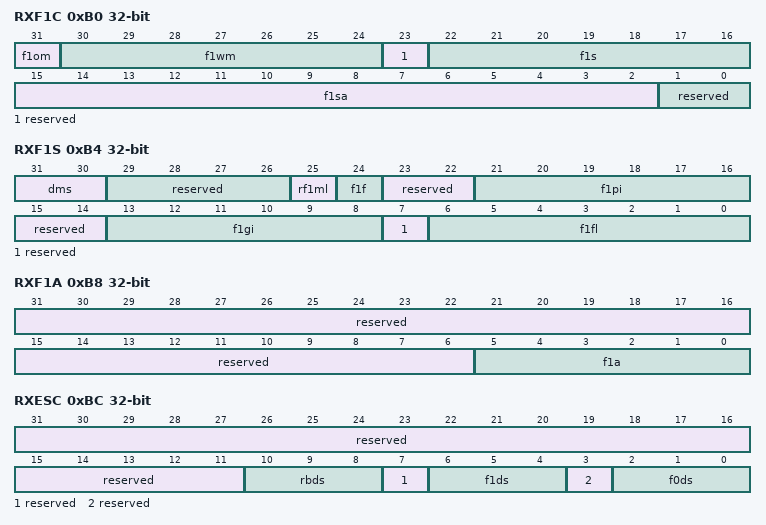
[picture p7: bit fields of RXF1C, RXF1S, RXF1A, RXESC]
0xB0 RXF1C — RXF1C为MCAN接收FIFO1配置寄存器。
  [31] f1om rw — 接收FIFO1操作模式。 FIFO1可工作在阻塞模式（Blocking mode）或覆盖模式（Overwrite mode）。 0：接收FIFO1为阻塞模式； 1：接收FIFO1为覆盖模式。
  [30:24] f1wm rw — 接收FIFO1水线。 0x00：禁止接收FIFO1水位线中断； 0x01~0x40：接收FIFO1水位线中断（IR[rf1w]）的级别； ＞0x40：禁止接收FIFO1水位线中断。
  [23] reserved ro — 保留。
  [22:16] f1s rw — 接收FIFO1大小。 0x00：无接收FIFO1； 0x01~0x40：接收FIFO1元素数量； ＞0x40：大于64的设定值被解析为64； 接收FIFO1元素的索引为0到F1S减1。
  [15:2] f1sa rw — 接收FIFO1起始地址。 消息RAM中接收FIFO1的起始地址（32位字地址）。
  [1:0] reserved ro — 保留。
0xB4 RXF1S ro — RXF1S为MCAN接收FIFO1状态寄存器。
  [31:30] dms — 调试消息状态。 00：空闲状态，等待接收调试消息； 01：已接收调试消息A； 10：已接收调试消息A、B； 11：已接收调试消息A、B、C。
  [29:26] reserved — 保留。
  [25] rf1ml — 接收FIFO1消息丢失。 0：接收FIFO1无元素丢失； 1：接收FIFO1有元素丢失；对空间大小为0的接收FIFO1进行写操作时，该位也会置位。 注意：当RXF1C[f1om]=1时，覆盖最早的消息，不会置位该标志位。
  [24] f1f — 接收FIFO1满。 0：接收FIFO1未满； 1：接收FIFO1已满。
  [23:22] reserved — 保留。
  [21:16] f1pi — 接收FIFO1放入索引。 接收FIFO1写入索引指针，范围0~63。
  [15:14] reserved — 保留。
  [13:8] f1gi — 接收FIFO1获取索引。 接收FIFO1读取索引指针，范围0~63。
  [7] reserved — 保留。
  [6:0] f1fl — 接收FIFO1填充级别。 接收FIFO1中存储的元素数量，范围0~64。
0xB8 RXF1A — RXF1A为MCAN接收FIFO1确认寄存器。
  [31:6] reserved ro — 保留。
  [5:0] f1a rw — 接收FIFO1确认索引。 主机从接收FIFO1读取消息或消息序列后，必须将从接收FIFO1中读取的最后一个元素的缓冲区索引写入F1AI。此操作会将接收FIFO1获取索引RXF1S[f1gi]设为F1AI加1，并会更新FIFO1填充级别RXF1S[f1fl]。
0xBC RXESC — RXESC为MCAN接收缓冲区和FIFO元素大小配置寄存器。配置接收缓冲区和接收FIFO元素的数据字节数。大于8Byte的数据场（Data field）仅适用于CAN-FD模式。
  [31:11] reserved ro — 保留。
  [10:8] rbds rw — 接收缓冲区数据场大小。 000：8Byte； 001：12Byte； 010：16Byte； 011：20Byte； 100：24Byte； 101：32Byte； 110：48Byte； 111：64Byte。
  [7] reserved ro — 保留。
  [6:4] f1ds rw — 接收FIFO1数场大小。 000：8Byte； 001：12Byte； 010：16Byte； 011：20Byte； 100：24Byte； 101：32Byte； 110：48Byte； 111：64Byte。
  [3] reserved ro — 保留。
  [2:0] f0ds rw — 接收FIFO0数据场大小。 000：8Byte； 001：12Byte； 010：16Byte； 011：20Byte； 100：24Byte； 101：32Byte； 110：48Byte； 111：64Byte。
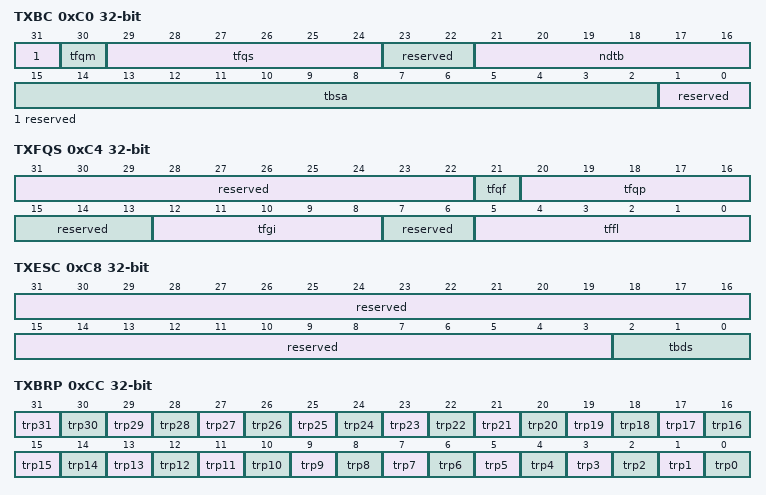
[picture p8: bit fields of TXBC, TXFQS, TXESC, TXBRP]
0xC0 TXBC — TXBC为MCAN发送缓冲区配置寄存器。仅当CCCR[cce]和CCCR[init]均被置1时，才能对该寄存器进行写访问。
  [31] reserved ro — 保留。
  [30] tfqm rw — 发送FIFO/队列模式。 0：发送FIFO模式； 1：发送队列模式。
  [29:24] tfqs rw — 发送FIFO/队列大小。 0x00：无发送FIFO或队列； 0x01~0x20：发送FIFO队列的缓冲区大小； ＞0x20：大于32的设定值被解析为32。
  [23:22] reserved ro — 保留。
  [21:16] ndtb rw — 专用发送缓冲区大小。 0x00：无专用发送缓冲区； 0x01~0x20：专用发送缓冲区大小； ＞0x20：大于32的设定值被解析为32。 注意：tfqs和ndtb之和不得大于32。MCAN没有对该设置错误的监测。消息RAM中的发送缓冲区部分从专用发送缓冲区开始。
  [15:2] tbsa rw — 发送缓冲区起始地址。 消息RAM中发送缓冲区部分的起始地址（32位字地址）。
  [1:0] reserved ro — 保留。
0xC4 TXFQS ro — TXFQS为MCAN发送FIFO/队列状态寄存器。发送FIFO或队列的状态与寄存器TXBRP中挂起的发送请求有关。因此，由于正在运行的发送扫描（TXBRP尚未更新），添加或取消请求的效果可能会延迟。 在专用发送缓冲区与发送FIFO或发送队列组合配置的情况下，放入索引和获取索引是指，从第一个专用发送缓冲区开始的发送缓冲区编号。 例如：对于有12个专用发送缓冲区和20个发送FIFO缓冲区的组合配置，放入索引15指向发送FIFO的第4个缓冲区。
  [31:22] reserved — 保留。
  [21] tfqf — 发送FIFO/队列满。 0：发送FIFO或队列未满； 1：发送FIFO或队列已满。
  [20:16] tfqp — 发送FIFO/队列放入索引。 发送FIFO或队列的放入索引指针，范围0~31。
  [15:13] reserved — 保留。
  [12:8] tfgi — 发送FIFO获取索引。 发送FIFO的读取索引指针，范围0~31。若已配置为发送队列模式（TXBC[tfqm]=1），则该位读取值为0。
  [7:6] reserved — 保留。
  [5:0] tffl — 发送FIFO空闲级别。 从TFGI开始的连续空闲的发送FIFO元素数量，范围0~32。若已配置为发送队列模式（TXBC[tfqm]=1），则该位读取值为0。
0xC8 TXESC — TXESC为MCAN发送缓冲区元素大小配置寄存器。配置发送缓冲区元素的数据字节数。大于8Byte的数据场（Data field）仅适用于CAN-FD模式。
  [31:3] reserved ro — 保留。
  [2:0] tbds rw — 发送缓冲区数据场大小。 000：8Byte； 001：12Byte； 010：16Byte； 011：20Byte； 100：24Byte； 101：32Byte； 110：48Byte； 111：64Byte。 注意：如果发送缓冲区元素的数据长度（由DLC配置），大于TBDS配置的数据长度，则发送缓冲区中未定义的数据Byte将会以0xCC（填充Byte）发送。
0xCC TXBRP ro — TXBRP为MCAN发送缓冲区请求挂起寄存器。
  [31] trp31 — 发送缓冲区31的发送请求挂起标志。 每个发送缓冲区都有自己的发送请求挂起位。这些位通过寄存器TXBAR置位；在请求的发送已完成，或请求的发送已通过寄存器TXBCR取消后复位。 只有TXBC配置了的发送缓冲区对应的TXBRP位才会置位。TXBRP位置位后会启动发送扫描（详见26.3.6 发送处理章节），以检查优先级最高的挂起的发送请求（即消息ID最小的发送缓冲区）。 取消发送请求会复位相应的TXBRP位。如果请求取消时发送已经开始，则无论发送是否成功，在发送结束时TXBRP位都会被复位。TXBRP位复位后，对应的取消请求位也会立即复位。 请求取消后，以下情况通过寄存器TXBCF指示取消已完成： 发送成功及相应的TXBTO位置位后； 取消时发送尚未开始； 发送因仲裁失败而中止； 帧发送期间发生错误。 在DAR模式下，所有发送在失败后都会自动取消。所有失败的发送，对应的TXBCF位都会置位。 0：无发送请求挂起； 1：发送请求挂起。 注意：在发送扫描期间置位的TXBRP位，在本次发送扫描期间被忽略，在此期间，如果请求取消这些发送，则发送被立即取消，对应的TXBRP位复位。
  [n] trp{n} (n=0..30) — 发送缓冲区{n}的发送请求挂起标志。
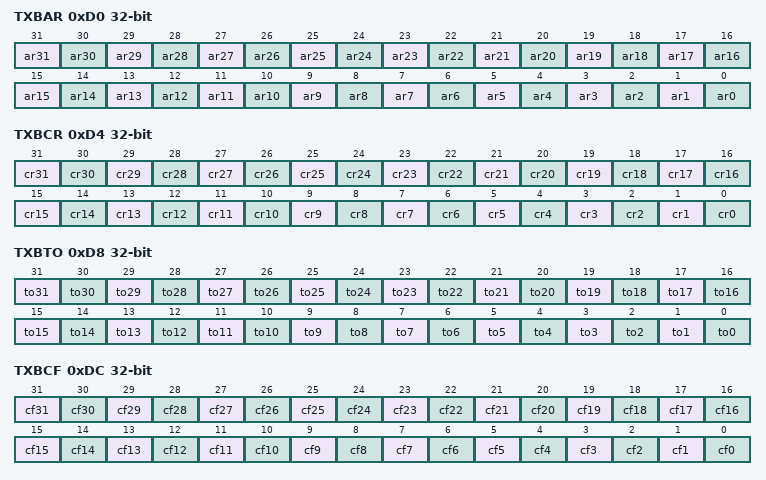
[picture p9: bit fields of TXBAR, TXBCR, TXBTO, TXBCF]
0xD0 TXBAR rw — TXBAR为MCAN发送缓冲区添加请求寄存器。
  [31] ar31 — 发送缓冲区31的添加请求。 每个发送缓冲区都有自己的添加请求位，写1置位相应的添加请求位，写0无影响。主机可一次设置多个发送缓冲区的发送请求。只有TXBC配置了的发送缓冲区对应的TXBAR位才会置位。没有运行发送扫描时，这些位立即复位，否则将保持置位到发送扫描完成。 0：未添加发送请求； 1：已添加发送请求。 注意：如果添加请求的发送缓冲区已有发送请求挂起（TXBRP寄存器相应位已置位），该添加请求将被忽略。
  [n] ar{n} (n=0..30) — 发送缓冲区{n}的添加请求。
0xD4 TXBCR rw — TXBCR为MCAN发送缓冲区取消请求寄存器。
  [31] cr31 — 发送缓冲区31的取消请求。 每个发送缓冲区都有自己的取消请求位，写1置位相应的取消请求位，写0无影响。主机可一次设置多个发送缓冲区的取消请求。只有TXBC配置了的发送缓冲区对应的TXBCR位才会置位。这些位保持置位直到对应的TXBRP位复位。 0：无取消请求挂起； 1：有取消请求挂起。
  [n] cr{n} (n=0..30) — 发送缓冲区{n}的取消请求。
0xD8 TXBTO ro — TXBTO为MCAN发送缓冲区发送已发生寄存器。
  [31] to31 — 发送缓冲区31的发送已发生。 每个发送缓冲区都有自己的发送已发生标志位。当发送缓冲区发送完成，TXBRP相应位清零时，对应的发送已发生标志位置位。向TXBAR相应位写1请求新的发送时，对应的发送已发生标志位复位。 0：未进行发送； 1：已进行发送。
  [n] to{n} (n=0..30) — 发送缓冲区{n}的发送已发生。
0xDC TXBCF ro — TXBCF为MCAN发送缓冲区取消已完成寄存器。
  [31] cf31 — 发送缓冲区31的取消已完成。 每个发送缓冲区都有自己的取消已完成标志位。当通过TXBCR请求的取消已完成，TXBRP相应位清零时，对应的取消已完成标志位置位。如果TXBRP相应位在取消时没有置位，取消已完成标志位会立即置位。向TXBAR相应位写1请求新的发送时，对应的取消已完成标志位复位。 0：无发送缓冲区取消； 1：发送缓冲区已取消。
  [n] cf{n} (n=0..30) — 发送缓冲区{n}的取消已完成。
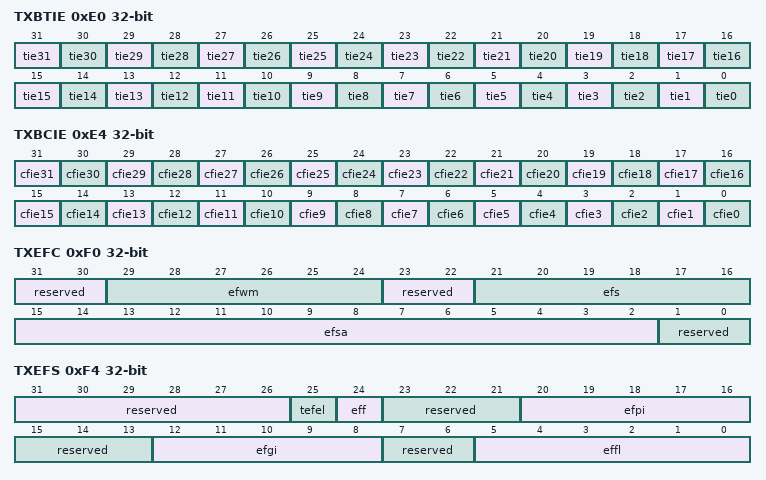
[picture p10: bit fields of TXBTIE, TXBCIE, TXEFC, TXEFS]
0xE0 TXBTIE rw — TXBTIE为MCAN发送缓冲区发送中断使能寄存器。
  [31] tie31 — 发送缓冲区31的发送中断使能。 每个发送缓冲区都有自己的发送中断使能位。 0：禁止发送中断； 1：使能发送中断。
  [n] tie{n} (n=0..30) — 发送缓冲区{n}的发送中断使能。
0xE4 TXBCIE rw — TXBCIE为MCAN发送缓冲区取消已完成中断使能寄存器。
  [31] cfie31 — 发送缓冲区31的取消已完成中断使能。 每个发送缓冲区都有自己的取消已完成中断使能位。 0：禁止取消已完成中断； 1：使能取消已完成中断。
  [n] cfie{n} (n=0..30) — 发送缓冲区{n}的取消已完成中断使能。
0xF0 TXEFC — TXEFC为MCAN发送事件FIFO配置寄存器。
  [31:30] reserved ro — 保留。
  [29:24] efwm rw — 事件FIFO水位线。 0x00：禁止水位线中断； 0x01~0x20：发送事件FIFO水位线中断（IR[tefw]）的级别； ＞0x20：禁止水位线中断。
  [23:22] reserved ro — 保留。
  [21:16] efs rw — 事件FIFO大小。 0x00：禁止发送事件FIFO； 0x01~0x20：发送事件FIFO的元素数量； ＞0x20：大于32的设定值被解析为32； 发送事件FIFO元素的索引为0到EFS减1。
  [15:2] efsa rw — 事件FIFO起始地址。 消息RAM中事件FIFO的起始地址（32位字地址）。
  [1:0] reserved ro — 保留。
0xF4 TXEFS ro — TXEFS为MCAN发送事件FIFO状态寄存器。
  [31:26] reserved — 保留。
  [25] tefel — 发送事件FIFO元素丢失。 该位是中断标志IR[tefl]的副本。当IR[tefl]被复位时，该位也被复位。 0：发送事件FIFO无元素丢失； 1：发送事件FIFO有元素丢失；对空间大小为0的发送事件FIFO进行写操作时，该位也会置位。
  [24] eff — 事件FIFO已满。 0：发送事件FIFO未满； 1：发送事件FIFO已满。
  [23:21] reserved — 保留。
  [20:16] efpi — 事件FIFO放入索引。 发送事件FIFO写入索引指针，范围0~31。
  [15:13] reserved — 保留。
  [12:8] efgi — 事件FIFO获取索引。 发送事件FIFO读取索引指针，范围0~31。
  [7:6] reserved — 保留。
  [5:0] effl — 事件FIFO填充级别。 接收FIFO0中存储的元素个数，范围0~32。
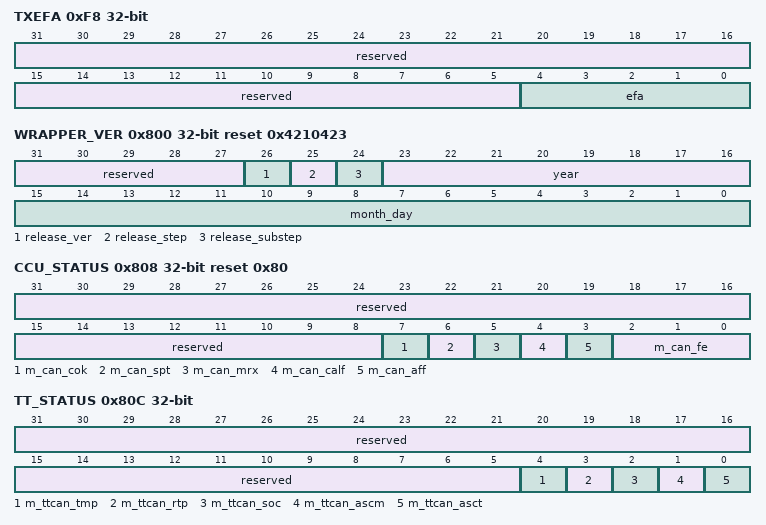
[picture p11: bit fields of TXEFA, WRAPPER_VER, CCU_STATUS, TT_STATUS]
0xF8 TXEFA — TXEFA为MCAN发送事件FIFO确认寄存器。
  [31:5] reserved ro — 保留。
  [4:0] efa rw — 事件FIFO确认索引。 主机从发送事件FIFO读取元素或元素序列后，必须将从事件FIFO中读取的最后一个元素的索引写入EFAI。此操作会将发送事件FIFO获取索引TXEFS[EFGI]设为EFAI加1，并会更新事件FIFO填充级别TXEFS[effl]。
0x800 WRAPPER_VER ro reset 0x4210423 — WRAPPER_VER为CAN版本信息寄存器。
  [31:27] reserved — 保留。
  [26] release_ver — 版本信息。
  [25] release_step — 版本信息。
  [24] release_substep — 版本信息。
  [23:16] year — 版本信息。
  [15:0] month_day — 版本信息。
0x808 CCU_STATUS ro reset 0x80 — CCU_STATUS为CCU状态。
  [31:8] reserved — 保留。
  [7] m_can_cok — calibration ok。
  [6] m_can_spt — sample point delayed by one m_can_cclk period。
  [5] m_can_mrx — message received。
  [4] m_can_calf — calibration field。
  [3] m_can_aff — acceptance filter finished。
  [2:0] m_can_fe — filter events 0, 1, 2。
0x80C TT_STATUS ro — TT_STATUS为TT状态。
  [31:5] reserved — 保留。
  [4] m_ttcan_tmp — TT trigger time mark interrupt pulse。
  [3] m_ttcan_rtp — TT register time mark interrupt pulse。
  [2] m_ttcan_soc — TT start of cycle。
  [1] m_ttcan_ascm — TT ASC multiplexer control。
  [0] m_ttcan_asct — TT ASC transmit control。
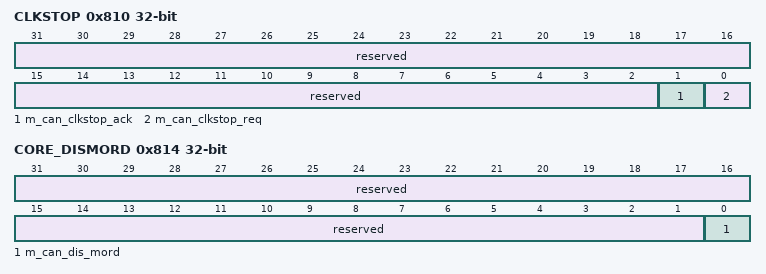
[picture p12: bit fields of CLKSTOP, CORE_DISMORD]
0x810 CLKSTOP — CLKSTOP为CAN关闭时钟寄存器。
  [31:2] reserved ro — 保留。
  [1] m_can_clkstop_ack ro — PCLK and CCLK clock stop acknowledge。
  [0] m_can_clkstop_req rw — PCLK and CCLK clock stop request。
0x814 CORE_DISMORD — CORE_DISMORD为读操作更改特性使能禁能寄存器。
  [31:1] reserved ro — 保留。
  [0] m_can_dis_mord rw — 禁止读操作时更改如下位域。 0：读清ECR[cel]，PSR[pxe]，PSR[rfdf]，PSR[rbrs]，PSR[resi]。读置位PSR[dlec]，PSR[lec]； 1：禁止上述操作。
